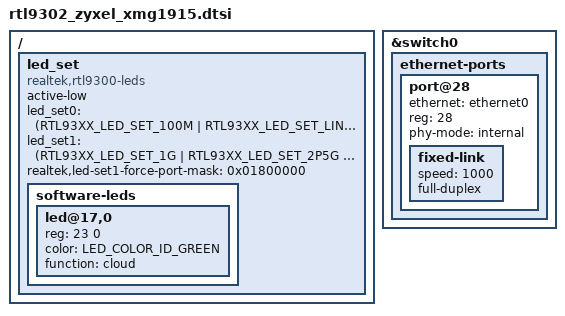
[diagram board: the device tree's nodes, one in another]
// SPDX-License-Identifier: GPL-2.0-or-later

/* The 10-port boards: XMG1915-10E and -10EP. */

#include "rtl9302_zyxel_xmg1915-common.dtsi"

/ {
	led_set: led_set {
		compatible = "realtek,rtl9300-leds";
		active-low;

		/* Copper */
		led_set0 = <(RTL93XX_LED_SET_100M | RTL93XX_LED_SET_LINK |
			     RTL93XX_LED_SET_ACT)
			    (RTL93XX_LED_SET_100M |RTL93XX_LED_SET_1G |
			     RTL93XX_LED_SET_2P5G | RTL93XX_LED_SET_LINK |
			     RTL93XX_LED_SET_ACT)
			    (RTL93XX_LED_SET_2P5G | RTL93XX_LED_SET_LINK |
			     RTL93XX_LED_SET_ACT)>;
		/* SFP+ */
		led_set1 = <(RTL93XX_LED_SET_1G | RTL93XX_LED_SET_2P5G |
			     RTL93XX_LED_SET_LINK | RTL93XX_LED_SET_ACT)
			     (RTL93XX_LED_SET_10G | RTL93XX_LED_SET_2P5G |
			     RTL93XX_LED_SET_LINK | RTL93XX_LED_SET_ACT)>;

		/* PoE and Cloud are 4 leds in total but software managed.
		   Assign them to led_set 1 to avoid shifting the others
		   incorrectly. */
		realtek,led-set1-force-port-mask = <0x01800000>;

		/*
		 * CLOUD and, on the PoE models, the PoE indicator, in the scan
		 * slots after the copper ports. CLOUD is slot 23 LED 0.
		 */
		software-leds {
			#address-cells = <2>;
			#size-cells = <0>;

			led@17,0 {
				reg = <23 0>;
				color = <LED_COLOR_ID_GREEN>;
				function = "cloud";
			};
		};
	};
};

&switch0 {
	ethernet-ports {
		#address-cells = <1>;
		#size-cells = <0>;

		/* Copper ports */
		SWITCH_PORT_LED(0, 1, 2, 0, 0, 10g-qxgmii)
		SWITCH_PORT_LED(1, 2, 2, 1, 0, 10g-qxgmii)
		SWITCH_PORT_LED(2, 3, 2, 2, 0, 10g-qxgmii)
		SWITCH_PORT_LED(3, 4, 2, 3, 0, 10g-qxgmii)
		SWITCH_PORT_LED(8, 5, 3, 0, 0, 10g-qxgmii)
		SWITCH_PORT_LED(9, 6, 3, 1, 0, 10g-qxgmii)
		SWITCH_PORT_LED(10, 7, 3, 2, 0, 10g-qxgmii)
		SWITCH_PORT_LED(11, 8, 3, 3, 0, 10g-qxgmii)

		/* SFP cages */
		SWITCH_PORT_SFP(25, 9, 7, 1, 0)
		SWITCH_PORT_SFP(27, 10, 9, 1, 1)

		port@28 {
			ethernet = <&ethernet0>;
			reg = <28>;
			phy-mode = "internal";
			fixed-link {
				speed = <1000>;
				full-duplex;
			};
		};
	};
};
